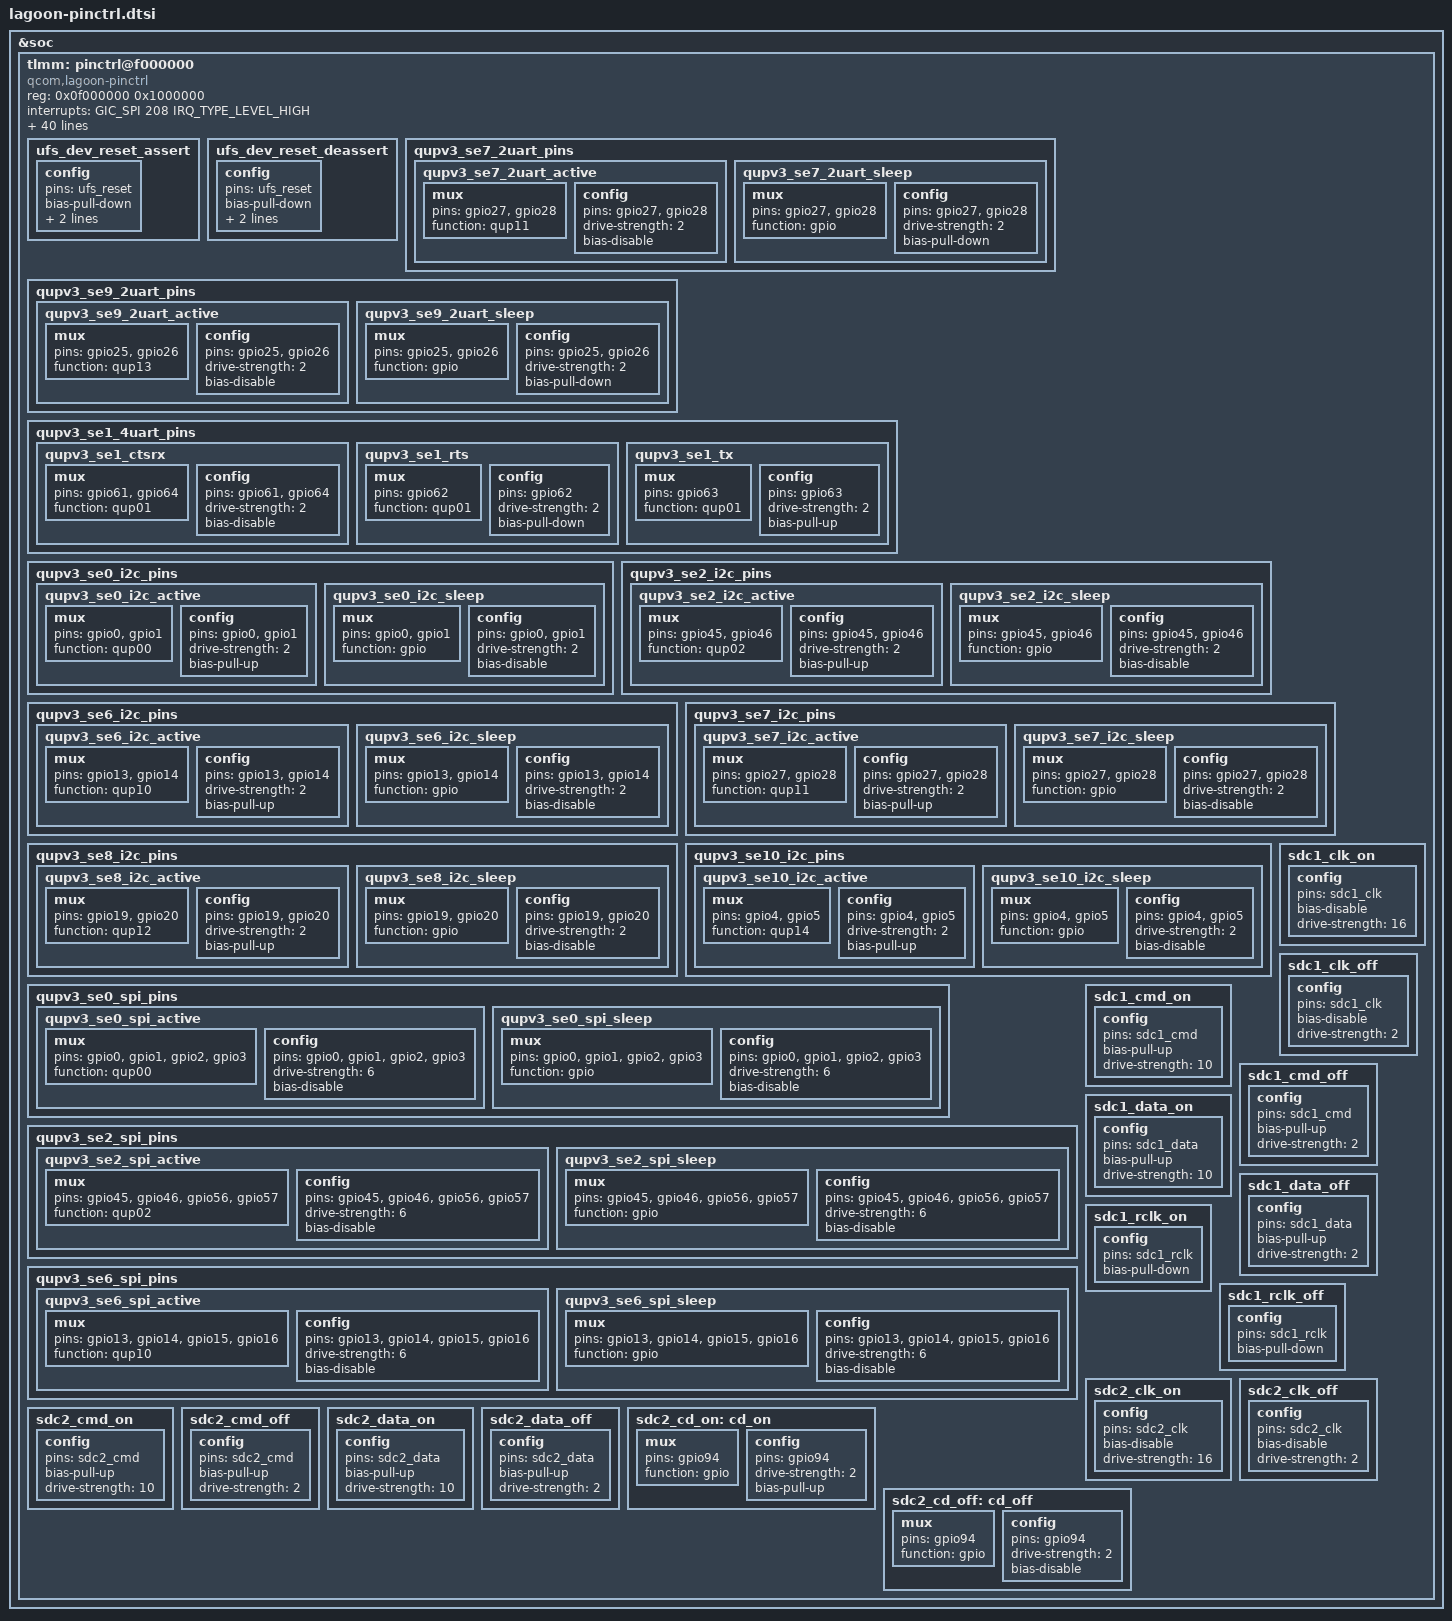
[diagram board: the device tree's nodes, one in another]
&soc {
	tlmm: pinctrl@f000000 {
		compatible = "qcom,lagoon-pinctrl";
		reg = <0x0f000000 0x1000000>;
		interrupts = <GIC_SPI 208 IRQ_TYPE_LEVEL_HIGH>;
		gpio-controller;
		#gpio-cells = <2>;
		interrupt-controller;
		#interrupt-cells = <2>;
		wakeup-parent = <&pdc>;
		irqdomain-map = <3 0 &pdc 126 0>,
				<4 0 &pdc 151 0>,
				<7 0 &pdc 58 0>,
				<8 0 &pdc 113 0>,
				<9 0 &pdc 66 0>,
				<11 0 &pdc 106 0>,
				<12 0 &pdc 59 0>,
				<13 0 &pdc 112 0>,
				<16 0 &pdc 73 0>,
				<17 0 &pdc 74 0>,
				<18 0 &pdc 75 0>,
				<19 0 &pdc 76 0>,
				<21 0 &pdc 130 0>,
				<22 0 &pdc 96 0>,
				<23 0 &pdc 146 0>,
				<24 0 &pdc 114 0>,
				<25 0 &pdc 83 0>,
				<27 0 &pdc 84 0>,
				<28 0 &pdc 85 0>,
				<34 0 &pdc 147 0>,
				<35 0 &pdc 92 0>,
				<36 0 &pdc 93 0>,
				<37 0 &pdc 94 0>,
				<38 0 &pdc 68 0>,
				<48 0 &pdc 100 0>,
				<50 0 &pdc 57 0>,
				<51 0 &pdc 81 0>,
				<52 0 &pdc 80 0>,
				<53 0 &pdc 69 0>,
				<54 0 &pdc 71 0>,
				<55 0 &pdc 70 0>,
				<57 0 &pdc 152 0>,
				<58 0 &pdc 115 0>,
				<59 0 &pdc 116 0>,
				<60 0 &pdc 117 0>,
				<61 0 &pdc 118 0>,
				<62 0 &pdc 119 0>,
				<64 0 &pdc 121 0>,
				<66 0 &pdc 127 0>,
				<67 0 &pdc 128 0>,
				<69 0 &pdc 60 0>,
				<73 0 &pdc 78 0>,
				<78 0 &pdc 135 0>,
				<82 0 &pdc 138 0>,
				<83 0 &pdc 140 0>,
				<84 0 &pdc 141 0>,
				<85 0 &pdc 98 0>,
				<87 0 &pdc 88 0>,
				<88 0 &pdc 107 0>,
				<89 0 &pdc 109 0>,
				<90 0 &pdc 110 0>,
				<91 0 &pdc 111 0>,
				<92 0 &pdc 149 0>,
				<93 0 &pdc 101 0>,
				<94 0 &pdc 61 0>,
				<95 0 &pdc 65 0>,
				<96 0 &pdc 95 0>,
				<97 0 &pdc 72 0>,
				<98 0 &pdc 145 0>,
				<99 0 &pdc 150 0>,
				<100 0 &pdc 108 0>,
				<104 0 &pdc 129 0>,
				<107 0 &pdc 131 0>,
				<110 0 &pdc 132 0>,
				<112 0 &pdc 133 0>,
				<114 0 &pdc 134 0>,
				<116 0 &pdc 136 0>,
				<118 0 &pdc 137 0>,
				<122 0 &pdc 97 0>,
				<123 0 &pdc 99 0>,
				<124 0 &pdc 148 0>,
				<125 0 &pdc 82 0>,
				<133 0 &pdc 142 0>,
				<134 0 &pdc 143 0>,
				<136 0 &pdc 102 0>,
				<137 0 &pdc 91 0>,
				<138 0 &pdc 77 0>,
				<139 0 &pdc 79 0>,
				<140 0 &pdc 90 0>,
				<142 0 &pdc 103 0>,
				<144 0 &pdc 105 0>,
				<147 0 &pdc 104 0>,
				<153 0 &pdc 120 0>;
		irqdomain-map-mask = <0xff 0>;
		irqdomain-map-pass-thru = <0 0xff>;

		ufs_dev_reset_assert: ufs_dev_reset_assert {
			config {
				pins = "ufs_reset";
				bias-pull-down;		/* default: pull down */
				/*
				 * UFS_RESET driver strengths are having
				 * different values/steps compared to typical
				 * GPIO drive strengths.
				 *
				 * Following table clarifies:
				 *
				 * HDRV value | UFS_RESET | Typical GPIO
				 *   (dec)    |   (mA)    |    (mA)
				 *     0      |   0.8     |    2
				 *     1      |   1.55    |    4
				 *     2      |   2.35    |    6
				 *     3      |   3.1     |    8
				 *     4      |   3.9     |    10
				 *     5      |   4.65    |    12
				 *     6      |   5.4     |    14
				 *     7      |   6.15    |    16
				 *
				 * POR value for UFS_RESET HDRV is 3 which means
				 * 3.1mA and we want to use that. Hence just
				 * specify 8mA to "drive-strength" binding and
				 * that should result into writing 3 to HDRV
				 * field.
				 */
				drive-strength = <8>;	/* default: 3.1 mA */
				output-low; /* active low reset */
			};
		};

		ufs_dev_reset_deassert: ufs_dev_reset_deassert {
			config {
				pins = "ufs_reset";
				bias-pull-down;		/* default: pull down */
				/*
				 * default: 3.1 mA
				 * check comments under ufs_dev_reset_assert
				 */
				drive-strength = <8>;
				output-high; /* active low reset */
			};
		};

		qupv3_se7_2uart_pins: qupv3_se7_2uart_pins {
			qupv3_se7_2uart_active: qupv3_se7_2uart_active {
				mux {
					pins = "gpio27", "gpio28";
					function = "qup11";
				};

				config {
					pins = "gpio27", "gpio28";
					drive-strength = <2>;
					bias-disable;
				};
			};

			qupv3_se7_2uart_sleep: qupv3_se7_2uart_sleep {
				mux {
					pins = "gpio27", "gpio28";
					function = "gpio";
				};

				config {
					pins = "gpio27", "gpio28";
					drive-strength = <2>;
					bias-pull-down;
				};
			};
		};

		qupv3_se9_2uart_pins: qupv3_se9_2uart_pins {
			qupv3_se9_2uart_active: qupv3_se9_2uart_active {
				mux {
					pins = "gpio25", "gpio26";
					function = "qup13";
				};

				config {
					pins = "gpio25", "gpio26";
					drive-strength = <2>;
					bias-disable;
				};
			};

			qupv3_se9_2uart_sleep: qupv3_se9_2uart_sleep {
				mux {
					pins = "gpio25", "gpio26";
					function = "gpio";
				};

				config {
					pins = "gpio25", "gpio26";
					drive-strength = <2>;
					bias-pull-down;
				};
			};
		};

		qupv3_se1_4uart_pins: qupv3_se1_4uart_pins {
			qupv3_se1_ctsrx: qupv3_se1_ctsrx {
				mux {
					pins = "gpio61", "gpio64";
					function = "qup01";
				};

				config {
					pins = "gpio61", "gpio64";
					drive-strength = <2>;
					bias-disable;
				};
			};

			qupv3_se1_rts: qupv3_se1_rts {
				mux {
					pins = "gpio62";
					function = "qup01";
				};

				config {
					pins = "gpio62";
					drive-strength = <2>;
					bias-pull-down;
				};
			};

			qupv3_se1_tx: qupv3_se1_tx {
				mux {
					pins = "gpio63";
					function = "qup01";
				};

				config {
					pins = "gpio63";
					drive-strength = <2>;
					bias-pull-up;
				};
			};
		};

		qupv3_se0_i2c_pins: qupv3_se0_i2c_pins {
			qupv3_se0_i2c_active: qupv3_se0_i2c_active {
				mux {
					pins = "gpio0", "gpio1";
					function = "qup00";
				};

				config {
					pins = "gpio0", "gpio1";
					drive-strength = <2>;
					bias-pull-up;
				};
			};

			qupv3_se0_i2c_sleep: qupv3_se0_i2c_sleep {
				mux {
					pins = "gpio0", "gpio1";
					function = "gpio";
				};

				config {
					pins = "gpio0", "gpio1";
					drive-strength = <2>;
					bias-disable;
				};
			};
		};

		qupv3_se2_i2c_pins: qupv3_se2_i2c_pins {
			qupv3_se2_i2c_active: qupv3_se2_i2c_active {
				mux {
					pins = "gpio45", "gpio46";
					function = "qup02";
				};

				config {
					pins = "gpio45", "gpio46";
					drive-strength = <2>;
					bias-pull-up;
				};
			};

			qupv3_se2_i2c_sleep: qupv3_se2_i2c_sleep {
				mux {
					pins = "gpio45", "gpio46";
					function = "gpio";
				};

				config {
					pins = "gpio45", "gpio46";
					drive-strength = <2>;
					bias-disable;
				};
			};
		};

		qupv3_se6_i2c_pins: qupv3_se6_i2c_pins {
			qupv3_se6_i2c_active: qupv3_se6_i2c_active {
				mux {
					pins = "gpio13", "gpio14";
					function = "qup10";
				};

				config {
					pins = "gpio13", "gpio14";
					drive-strength = <2>;
					bias-pull-up;
				};
			};

			qupv3_se6_i2c_sleep: qupv3_se6_i2c_sleep {
				mux {
					pins = "gpio13", "gpio14";
					function = "gpio";
				};

				config {
					pins = "gpio13", "gpio14";
					drive-strength = <2>;
					bias-disable;
				};
			};
		};

		qupv3_se7_i2c_pins: qupv3_se7_i2c_pins {
			qupv3_se7_i2c_active: qupv3_se7_i2c_active {
				mux {
					pins = "gpio27", "gpio28";
					function = "qup11";
				};

				config {
					pins = "gpio27", "gpio28";
					drive-strength = <2>;
					bias-pull-up;
				};
			};

			qupv3_se7_i2c_sleep: qupv3_se7_i2c_sleep {
				mux {
					pins = "gpio27", "gpio28";
					function = "gpio";
				};

				config {
					pins = "gpio27", "gpio28";
					drive-strength = <2>;
					bias-disable;
				};
			};
		};

		qupv3_se8_i2c_pins: qupv3_se8_i2c_pins {
			qupv3_se8_i2c_active: qupv3_se8_i2c_active {
				mux {
					pins = "gpio19", "gpio20";
					function = "qup12";
				};

				config {
					pins = "gpio19", "gpio20";
					drive-strength = <2>;
					bias-pull-up;
				};
			};

			qupv3_se8_i2c_sleep: qupv3_se8_i2c_sleep {
				mux {
					pins = "gpio19", "gpio20";
					function = "gpio";
				};

				config {
					pins = "gpio19", "gpio20";
					drive-strength = <2>;
					bias-disable;
				};
			};
		};

		qupv3_se10_i2c_pins: qupv3_se10_i2c_pins {
			qupv3_se10_i2c_active: qupv3_se10_i2c_active {
				mux {
					pins = "gpio4", "gpio5";
					function = "qup14";
				};

				config {
					pins = "gpio4", "gpio5";
					drive-strength = <2>;
					bias-pull-up;
				};
			};

			qupv3_se10_i2c_sleep: qupv3_se10_i2c_sleep {
				mux {
					pins = "gpio4", "gpio5";
					function = "gpio";
				};

				config {
					pins = "gpio4", "gpio5";
					drive-strength = <2>;
					bias-disable;
				};
			};
		};

		qupv3_se0_spi_pins: qupv3_se0_spi_pins {
			qupv3_se0_spi_active: qupv3_se0_spi_active {
				mux {
					pins = "gpio0", "gpio1",
							"gpio2", "gpio3";
					function = "qup00";
				};

				config {
					pins = "gpio0", "gpio1",
							"gpio2", "gpio3";
					drive-strength = <6>;
					bias-disable;
				};
			};

			qupv3_se0_spi_sleep: qupv3_se0_spi_sleep {
				mux {
					pins = "gpio0", "gpio1",
							"gpio2", "gpio3";
					function = "gpio";
				};

				config {
					pins = "gpio0", "gpio1",
							"gpio2", "gpio3";
					drive-strength = <6>;
					bias-disable;
				};
			};
		};

		qupv3_se2_spi_pins: qupv3_se2_spi_pins {
			qupv3_se2_spi_active: qupv3_se2_spi_active {
				mux {
					pins = "gpio45", "gpio46",
							"gpio56", "gpio57";
					function = "qup02";
				};

				config {
					pins = "gpio45", "gpio46",
							"gpio56", "gpio57";
					drive-strength = <6>;
					bias-disable;
				};
			};

			qupv3_se2_spi_sleep: qupv3_se2_spi_sleep {
				mux {
					pins = "gpio45", "gpio46",
							"gpio56", "gpio57";
					function = "gpio";
				};

				config {
					pins = "gpio45", "gpio46",
							"gpio56", "gpio57";
					drive-strength = <6>;
					bias-disable;
				};
			};
		};

		qupv3_se6_spi_pins: qupv3_se6_spi_pins {
			qupv3_se6_spi_active: qupv3_se6_spi_active {
				mux {
					pins = "gpio13", "gpio14",
							"gpio15", "gpio16";
					function = "qup10";
				};

				config {
					pins = "gpio13", "gpio14",
							"gpio15", "gpio16";
					drive-strength = <6>;
					bias-disable;
				};
			};

			qupv3_se6_spi_sleep: qupv3_se6_spi_sleep {
				mux {
					pins = "gpio13", "gpio14",
							"gpio15", "gpio16";
					function = "gpio";
				};

				config {
					pins = "gpio13", "gpio14",
							"gpio15", "gpio16";
					drive-strength = <6>;
					bias-disable;
				};
			};
		};

		/* SDC pin type */
		sdc1_clk_on: sdc1_clk_on {
			config {
				pins = "sdc1_clk";
				bias-disable;		/* No pull */
				drive-strength = <16>;	/* 16 MA */
			};
		};

		sdc1_clk_off: sdc1_clk_off {
			config {
				pins = "sdc1_clk";
				bias-disable;		/* No Pull */
				drive-strength = <2>;	/* 2 MA */
			};
		};

		sdc1_cmd_on: sdc1_cmd_on {
			config {
				pins = "sdc1_cmd";
				bias-pull-up;		/* Pull up */
				drive-strength = <10>;	/* 10 MA */
			};
		};

		sdc1_cmd_off: sdc1_cmd_off {
			config {
				pins = "sdc1_cmd";
				bias-pull-up;		/* Pull up */
				drive-strength = <2>;	/* 2 MA */
			};
		};

		sdc1_data_on: sdc1_data_on {
			config {
				pins = "sdc1_data";
				bias-pull-up;		/* Pull up */
				drive-strength = <10>;	/* 10 MA */
			};
		};

		sdc1_data_off: sdc1_data_off {
			config {
				pins = "sdc1_data";
				bias-pull-up;		/* Pull up */
				drive-strength = <2>;	/* 2 MA */
			};
		};

		sdc1_rclk_on: sdc1_rclk_on {
			config {
				pins = "sdc1_rclk";
				bias-pull-down;		/* Pull down */
			};
		};

		sdc1_rclk_off: sdc1_rclk_off {
			config {
				pins = "sdc1_rclk";
				bias-pull-down;		/* Pull down */
			};
		};

		sdc2_clk_on: sdc2_clk_on {
			config {
				pins = "sdc2_clk";
				bias-disable;		/* No pull */
				drive-strength = <16>;	/* 16 MA */
			};
		};

		sdc2_clk_off: sdc2_clk_off {
			config {
				pins = "sdc2_clk";
				bias-disable;		/* No pull */
				drive-strength = <2>;	/* 2 MA */
			};
		};

		sdc2_cmd_on: sdc2_cmd_on {
			config {
				pins = "sdc2_cmd";
				bias-pull-up;		/* Pull up */
				drive-strength = <10>;	/* 10 MA */
			};
		};

		sdc2_cmd_off: sdc2_cmd_off {
			config {
				pins = "sdc2_cmd";
				bias-pull-up;		/* Pull up */
				drive-strength = <2>;	/* 2 MA */
			};
		};

		sdc2_data_on: sdc2_data_on {
			config {
				pins = "sdc2_data";
				bias-pull-up;		/* Pull up */
				drive-strength = <10>;	/* 10 MA */
			};
		};

		sdc2_data_off: sdc2_data_off {
			config {
				pins = "sdc2_data";
				bias-pull-up;		/* Pull up */
				drive-strength = <2>;	/* 2 MA */
			};
		};

		sdc2_cd_on: cd_on {
			mux {
				pins = "gpio94";
				function = "gpio";
			};

			config {
				pins = "gpio94";
				drive-strength = <2>;
				bias-pull-up;
			};
		};

		sdc2_cd_off: cd_off {
			mux {
				pins = "gpio94";
				function = "gpio";
			};

			config {
				pins = "gpio94";
				drive-strength = <2>;
				bias-disable;
			};
		};
	};
};
